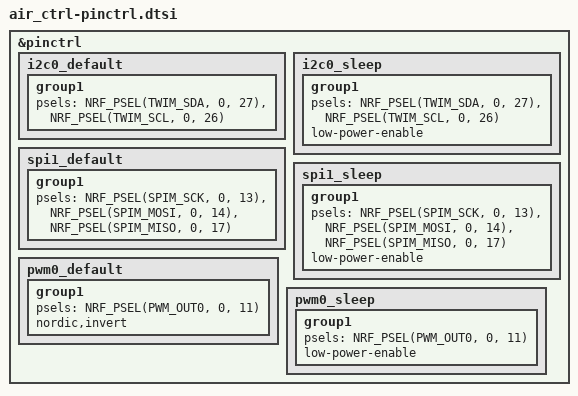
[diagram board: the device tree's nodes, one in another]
&pinctrl {
	i2c0_default: i2c0_default {
		group1 {
			psels = <NRF_PSEL(TWIM_SDA, 0, 27)>,
			        <NRF_PSEL(TWIM_SCL, 0, 26)>;
		};
	};

	i2c0_sleep: i2c0_sleep {
		group1 {
			psels = <NRF_PSEL(TWIM_SDA, 0, 27)>,
			        <NRF_PSEL(TWIM_SCL, 0, 26)>;
			low-power-enable;
		};
	};

    spi1_default: spi1_default {
		group1 {
			psels = <NRF_PSEL(SPIM_SCK, 0, 13)>,
					<NRF_PSEL(SPIM_MOSI, 0, 14)>,
					<NRF_PSEL(SPIM_MISO, 0, 17)>;
		};
	};

	spi1_sleep: spi1_sleep {
		group1 {
			psels = <NRF_PSEL(SPIM_SCK, 0, 13)>,
					<NRF_PSEL(SPIM_MOSI, 0, 14)>,
					<NRF_PSEL(SPIM_MISO, 0, 17)>;
			low-power-enable;
		};
	};

	pwm0_default: pwm0_default {
		group1 {
			psels = <NRF_PSEL(PWM_OUT0, 0, 11)>;
			nordic,invert;
		};
	};

	pwm0_sleep: pwm0_sleep {
		group1 {
			psels = <NRF_PSEL(PWM_OUT0, 0, 11)>;
			low-power-enable;
		};
	};
};
